# MCXC444 register map
Vendor: NXP Semiconductors; Series: MCX; File version: 1.6
CPU: CM0PLUS r0p0, little endian, no MPU, no FPU, VTOR, 2 interrupt priority bits
Registers are 32-bit, read-write, reset 0x0 unless marked. A register's access mark holds for its fields unless they carry their own. Offsets are from the block's base; [hi:lo] are bit positions; 'fields as' and 'values as' point back to an identical list.

## RCM — Reset Control Module
Base 0x4007F000; register names take the prefix RCM_
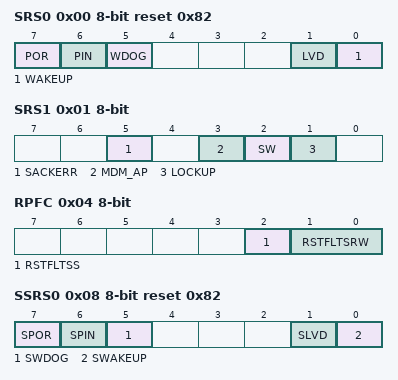
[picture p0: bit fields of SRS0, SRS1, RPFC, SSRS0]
0x00 SRS0 8-bit ro reset 0x82 — System Reset Status Register 0
  [7] POR — Power-On Reset
    0=b0 (Reset not caused by POR); 1=b1 (Reset caused by POR)
  [6] PIN — External Reset Pin
    0=b0 (Reset not caused by external reset pin); 1=b1 (Reset caused by external reset pin)
  [5] WDOG — Watchdog
    0=b0 (Reset not caused by watchdog timeout); 1=b1 (Reset caused by watchdog timeout)
  [1] LVD — Low-Voltage Detect Reset
    0=b0 (Reset not caused by LVD trip or POR); 1=b1 (Reset caused by LVD trip or POR)
  [0] WAKEUP — Low Leakage Wakeup Reset
    0=b0 (Reset not caused by LLWU module wakeup source); 1=b1 (Reset caused by LLWU module wakeup source)
0x01 SRS1 8-bit ro — System Reset Status Register 1
  [5] SACKERR — Stop Mode Acknowledge Error Reset
    0=b0 (Reset not caused by peripheral failure to acknowledge attempt to enter stop mode); 1=b1 (Reset caused by peripheral failure to acknowledge attempt to enter stop mode)
  [3] MDM_AP — MDM-AP System Reset Request
    0=b0 (Reset not caused by host debugger system setting of the System Reset Request bit); 1=b1 (Reset caused by host debugger system setting of the System Reset Request bit)
  [2] SW — Software
    0=b0 (Reset not caused by software setting of SYSRESETREQ bit); 1=b1 (Reset caused by software setting of SYSRESETREQ bit)
  [1] LOCKUP — Core Lockup
    0=b0 (Reset not caused by core LOCKUP event); 1=b1 (Reset caused by core LOCKUP event)
0x04 RPFC 8-bit — Reset Pin Filter Control register
  [2] RSTFLTSS — Reset Pin Filter Select in Stop Mode
    0=b0 (All filtering disabled); 1=b1 (LPO clock filter enabled)
  [1:0] RSTFLTSRW — Reset Pin Filter Select in Run and Wait Modes
    0=b00 (All filtering disabled); 1=b01 (Bus clock filter enabled for normal operation); 2=b10 (LPO clock filter enabled for normal operation)
0x05 RPFW 8-bit — Reset Pin Filter Width register
  [4:0] RSTFLTSEL — Reset Pin Filter Bus Clock Select
    0=b00000 (Bus clock filter count is 1); 1=b00001 (Bus clock filter count is 2); 2=b00010 (Bus clock filter count is 3); 3=b00011 (Bus clock filter count is 4); 4=b00100 (Bus clock filter count is 5); 5=b00101 (Bus clock filter count is 6); 6=b00110 (Bus clock filter count is 7); 7=b00111 (Bus clock filter count is 8); 8=b01000 (Bus clock filter count is 9); 9=b01001 (Bus clock filter count is 10); 10=b01010 (Bus clock filter count is 11); 11=b01011 (Bus clock filter count is 12); 12=b01100 (Bus clock filter count is 13); 13=b01101 (Bus clock filter count is 14); 14=b01110 (Bus clock filter count is 15); 15=b01111 (Bus clock filter count is 16); 16=b10000 (Bus clock filter count is 17); 17=b10001 (Bus clock filter count is 18); 18=b10010 (Bus clock filter count is 19); 19=b10011 (Bus clock filter count is 20); 20=b10100 (Bus clock filter count is 21); 21=b10101 (Bus clock filter count is 22); 22=b10110 (Bus clock filter count is 23); 23=b10111 (Bus clock filter count is 24); 24=b11000 (Bus clock filter count is 25); 25=b11001 (Bus clock filter count is 26); 26=b11010 (Bus clock filter count is 27); 27=b11011 (Bus clock filter count is 28); 28=b11100 (Bus clock filter count is 29); 29=b11101 (Bus clock filter count is 30); 30=b11110 (Bus clock filter count is 31); 31=b11111 (Bus clock filter count is 32)
0x06 FM 8-bit — Force Mode Register
  [2:1] FORCEROM — Force ROM Boot
    0=b00 (No effect); 1=b01 (Force boot from ROM with RCM_MR[1] set.); 2=b10 (Force boot from ROM with RCM_MR[2] set.); 3=b11 (Force boot from ROM with RCM_MR[2:1] set.)
0x07 MR 8-bit — Mode Register
  [2:1] BOOTROM — Boot ROM Configuration
    0=b00 (Boot from Flash); 1=b01 (Boot from ROM due to BOOTCFG0 pin assertion); 2=b10 (Boot form ROM due to FOPT[7] configuration); 3=b11 (Boot from ROM due to both BOOTCFG0 pin assertion and FOPT[7] configuration)
0x08 SSRS0 8-bit reset 0x82 — Sticky System Reset Status Register 0
  [7] SPOR — Sticky Power-On Reset
    0=b0 (Reset not caused by POR); 1=b1 (Reset caused by POR)
  [6] SPIN — Sticky External Reset Pin
    values as SRS0.PIN
  [5] SWDOG — Sticky Watchdog
    values as SRS0.WDOG
  [1] SLVD — Sticky Low-Voltage Detect Reset
    values as SRS0.LVD
  [0] SWAKEUP — Sticky Low Leakage Wakeup Reset
    values as SRS0.WAKEUP
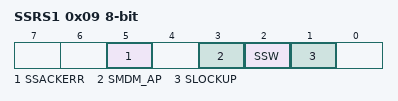
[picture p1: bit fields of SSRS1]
0x09 SSRS1 8-bit — Sticky System Reset Status Register 1
  [5] SSACKERR — Sticky Stop Mode Acknowledge Error Reset
    values as SRS1.SACKERR
  [3] SMDM_AP — Sticky MDM-AP System Reset Request
    values as SRS1.MDM_AP
  [2] SSW — Sticky Software
    values as SRS1.SW
  [1] SLOCKUP — Sticky Core Lockup
    values as SRS1.LOCKUP
